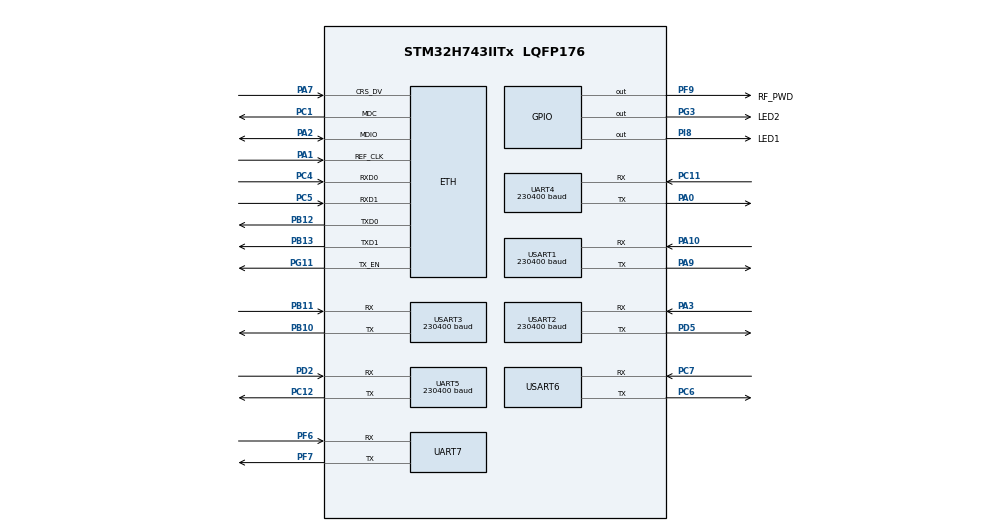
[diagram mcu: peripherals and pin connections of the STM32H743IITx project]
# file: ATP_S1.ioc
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CORTEX_M7.AccessPermission_S-Cortex_Memory_Protection_Unit_Region1_Settings_S=MPU_REGION_FULL_ACCESS
CORTEX_M7.BaseAddress_S-Cortex_Memory_Protection_Unit_Region1_Settings_S=0x30000000
CORTEX_M7.CPU_DCache=Enabled
CORTEX_M7.CPU_ICache=Enabled
CORTEX_M7.DisableExec_S-Cortex_Memory_Protection_Unit_Region1_Settings_S=MPU_INSTRUCTION_ACCESS_DISABLE
CORTEX_M7.Enable_S-Cortex_Memory_Protection_Unit_Region1_Settings_S=MPU_REGION_ENABLE
CORTEX_M7.IsShareable_S-Cortex_Memory_Protection_Unit_Region1_Settings_S=MPU_ACCESS_SHAREABLE
CORTEX_M7.Size_S-Cortex_Memory_Protection_Unit_Region1_Settings_S=MPU_REGION_SIZE_32KB
CORTEX_M7.TypeExtField_S-Cortex_Memory_Protection_Unit_Region1_Settings_S=MPU_TEX_LEVEL1
CORTEX_M7.default_mode_Activation=1
Dma.Request0=USART2_RX
Dma.Request1=USART2_TX
Dma.Request10=UART7_RX
Dma.Request11=UART7_TX
Dma.Request2=USART3_RX
Dma.Request3=USART3_TX
Dma.Request4=USART6_RX
Dma.Request5=USART6_TX
Dma.Request6=UART4_RX
Dma.Request7=UART4_TX
Dma.Request8=UART5_RX
Dma.Request9=UART5_TX
Dma.UART4_RX.6.Direction=DMA_PERIPH_TO_MEMORY
Dma.UART4_RX.6.EventEnable=DISABLE
Dma.UART4_RX.6.FIFOMode=DMA_FIFOMODE_DISABLE
Dma.UART4_RX.6.Instance=DMA1_Stream6
Dma.UART4_RX.6.MemDataAlignment=DMA_MDATAALIGN_BYTE
Dma.UART4_RX.6.MemInc=DMA_MINC_ENABLE
Dma.UART4_RX.6.Mode=DMA_NORMAL
Dma.UART4_RX.6.PeriphDataAlignment=DMA_PDATAALIGN_BYTE
Dma.UART4_RX.6.PeriphInc=DMA_PINC_DISABLE
Dma.UART4_RX.6.Polarity=HAL_DMAMUX_REQ_GEN_RISING
Dma.UART4_RX.6.Priority=DMA_PRIORITY_LOW
Dma.UART4_RX.6.RequestNumber=1
Dma.UART4_RX.6.SignalID=NONE
Dma.UART4_RX.6.SyncEnable=DISABLE
Dma.UART4_RX.6.SyncPolarity=HAL_DMAMUX_SYNC_NO_EVENT
Dma.UART4_RX.6.SyncRequestNumber=1
Dma.UART4_RX.6.SyncSignalID=NONE
Dma.UART4_TX.7.Direction=DMA_MEMORY_TO_PERIPH
Dma.UART4_TX.7.EventEnable=DISABLE
Dma.UART4_TX.7.FIFOMode=DMA_FIFOMODE_DISABLE
Dma.UART4_TX.7.Instance=DMA1_Stream7
Dma.UART4_TX.7.MemDataAlignment=DMA_MDATAALIGN_BYTE
Dma.UART4_TX.7.MemInc=DMA_MINC_ENABLE
Dma.UART4_TX.7.Mode=DMA_NORMAL
Dma.UART4_TX.7.PeriphDataAlignment=DMA_PDATAALIGN_BYTE
Dma.UART4_TX.7.PeriphInc=DMA_PINC_DISABLE
Dma.UART4_TX.7.Polarity=HAL_DMAMUX_REQ_GEN_RISING
Dma.UART4_TX.7.Priority=DMA_PRIORITY_LOW
Dma.UART4_TX.7.RequestNumber=1
Dma.UART4_TX.7.SignalID=NONE
Dma.UART4_TX.7.SyncEnable=DISABLE
Dma.UART4_TX.7.SyncPolarity=HAL_DMAMUX_SYNC_NO_EVENT
Dma.UART4_TX.7.SyncRequestNumber=1
Dma.UART4_TX.7.SyncSignalID=NONE
Dma.UART5_RX.8.Direction=DMA_PERIPH_TO_MEMORY
Dma.UART5_RX.8.EventEnable=DISABLE
Dma.UART5_RX.8.FIFOMode=DMA_FIFOMODE_DISABLE
Dma.UART5_RX.8.Instance=DMA2_Stream0
Dma.UART5_RX.8.MemDataAlignment=DMA_MDATAALIGN_BYTE
Dma.UART5_RX.8.MemInc=DMA_MINC_ENABLE
Dma.UART5_RX.8.Mode=DMA_NORMAL
Dma.UART5_RX.8.PeriphDataAlignment=DMA_PDATAALIGN_BYTE
Dma.UART5_RX.8.PeriphInc=DMA_PINC_DISABLE
Dma.UART5_RX.8.Polarity=HAL_DMAMUX_REQ_GEN_RISING
Dma.UART5_RX.8.Priority=DMA_PRIORITY_LOW
Dma.UART5_RX.8.RequestNumber=1
Dma.UART5_RX.8.SignalID=NONE
Dma.UART5_RX.8.SyncEnable=DISABLE
Dma.UART5_RX.8.SyncPolarity=HAL_DMAMUX_SYNC_NO_EVENT
Dma.UART5_RX.8.SyncRequestNumber=1
Dma.UART5_RX.8.SyncSignalID=NONE
Dma.UART5_TX.9.Direction=DMA_MEMORY_TO_PERIPH
Dma.UART5_TX.9.EventEnable=DISABLE
Dma.UART5_TX.9.FIFOMode=DMA_FIFOMODE_DISABLE
Dma.UART5_TX.9.Instance=DMA2_Stream1
Dma.UART5_TX.9.MemDataAlignment=DMA_MDATAALIGN_BYTE
Dma.UART5_TX.9.MemInc=DMA_MINC_ENABLE
Dma.UART5_TX.9.Mode=DMA_NORMAL
Dma.UART5_TX.9.PeriphDataAlignment=DMA_PDATAALIGN_BYTE
Dma.UART5_TX.9.PeriphInc=DMA_PINC_DISABLE
Dma.UART5_TX.9.Polarity=HAL_DMAMUX_REQ_GEN_RISING
Dma.UART5_TX.9.Priority=DMA_PRIORITY_LOW
Dma.UART5_TX.9.RequestNumber=1
Dma.UART5_TX.9.SignalID=NONE
Dma.UART5_TX.9.SyncEnable=DISABLE
Dma.UART5_TX.9.SyncPolarity=HAL_DMAMUX_SYNC_NO_EVENT
Dma.UART5_TX.9.SyncRequestNumber=1
Dma.UART5_TX.9.SyncSignalID=NONE
Dma.UART7_RX.10.Direction=DMA_PERIPH_TO_MEMORY
Dma.UART7_RX.10.EventEnable=DISABLE
Dma.UART7_RX.10.FIFOMode=DMA_FIFOMODE_DISABLE
Dma.UART7_RX.10.Instance=DMA2_Stream2
Dma.UART7_RX.10.MemDataAlignment=DMA_MDATAALIGN_BYTE
Dma.UART7_RX.10.MemInc=DMA_MINC_ENABLE
Dma.UART7_RX.10.Mode=DMA_NORMAL
Dma.UART7_RX.10.PeriphDataAlignment=DMA_PDATAALIGN_BYTE
Dma.UART7_RX.10.PeriphInc=DMA_PINC_DISABLE
Dma.UART7_RX.10.Polarity=HAL_DMAMUX_REQ_GEN_RISING
Dma.UART7_RX.10.Priority=DMA_PRIORITY_LOW
Dma.UART7_RX.10.RequestNumber=1
Dma.UART7_RX.10.SignalID=NONE
Dma.UART7_RX.10.SyncEnable=DISABLE
Dma.UART7_RX.10.SyncPolarity=HAL_DMAMUX_SYNC_NO_EVENT
Dma.UART7_RX.10.SyncRequestNumber=1
Dma.UART7_RX.10.SyncSignalID=NONE
Dma.UART7_TX.11.Direction=DMA_MEMORY_TO_PERIPH
Dma.UART7_TX.11.EventEnable=DISABLE
Dma.UART7_TX.11.FIFOMode=DMA_FIFOMODE_DISABLE
Dma.UART7_TX.11.Instance=DMA2_Stream3
Dma.UART7_TX.11.MemDataAlignment=DMA_MDATAALIGN_BYTE
Dma.UART7_TX.11.MemInc=DMA_MINC_ENABLE
Dma.UART7_TX.11.Mode=DMA_NORMAL
Dma.UART7_TX.11.PeriphDataAlignment=DMA_PDATAALIGN_BYTE
Dma.UART7_TX.11.PeriphInc=DMA_PINC_DISABLE
Dma.UART7_TX.11.Polarity=HAL_DMAMUX_REQ_GEN_RISING
Dma.UART7_TX.11.Priority=DMA_PRIORITY_LOW
Dma.UART7_TX.11.RequestNumber=1
Dma.UART7_TX.11.SignalID=NONE
Dma.UART7_TX.11.SyncEnable=DISABLE
Dma.UART7_TX.11.SyncPolarity=HAL_DMAMUX_SYNC_NO_EVENT
Dma.UART7_TX.11.SyncRequestNumber=1
Dma.UART7_TX.11.SyncSignalID=NONE
Dma.USART2_RX.0.Direction=DMA_PERIPH_TO_MEMORY
Dma.USART2_RX.0.EventEnable=DISABLE
Dma.USART2_RX.0.FIFOMode=DMA_FIFOMODE_DISABLE
Dma.USART2_RX.0.Instance=DMA1_Stream0
Dma.USART2_RX.0.MemDataAlignment=DMA_MDATAALIGN_BYTE
Dma.USART2_RX.0.MemInc=DMA_MINC_ENABLE
Dma.USART2_RX.0.Mode=DMA_NORMAL
Dma.USART2_RX.0.PeriphDataAlignment=DMA_PDATAALIGN_BYTE
Dma.USART2_RX.0.PeriphInc=DMA_PINC_DISABLE
Dma.USART2_RX.0.Polarity=HAL_DMAMUX_REQ_GEN_RISING
Dma.USART2_RX.0.Priority=DMA_PRIORITY_LOW
Dma.USART2_RX.0.RequestNumber=1
Dma.USART2_RX.0.SignalID=NONE
Dma.USART2_RX.0.SyncEnable=DISABLE
Dma.USART2_RX.0.SyncPolarity=HAL_DMAMUX_SYNC_NO_EVENT
Dma.USART2_RX.0.SyncRequestNumber=1
Dma.USART2_RX.0.SyncSignalID=NONE
Dma.USART2_TX.1.Direction=DMA_MEMORY_TO_PERIPH
Dma.USART2_TX.1.EventEnable=DISABLE
Dma.USART2_TX.1.FIFOMode=DMA_FIFOMODE_DISABLE
Dma.USART2_TX.1.Instance=DMA1_Stream1
Dma.USART2_TX.1.MemDataAlignment=DMA_MDATAALIGN_BYTE
Dma.USART2_TX.1.MemInc=DMA_MINC_ENABLE
Dma.USART2_TX.1.Mode=DMA_NORMAL
Dma.USART2_TX.1.PeriphDataAlignment=DMA_PDATAALIGN_BYTE
Dma.USART2_TX.1.PeriphInc=DMA_PINC_DISABLE
Dma.USART2_TX.1.Polarity=HAL_DMAMUX_REQ_GEN_RISING
Dma.USART2_TX.1.Priority=DMA_PRIORITY_LOW
Dma.USART2_TX.1.RequestNumber=1
Dma.USART2_TX.1.SignalID=NONE
Dma.USART2_TX.1.SyncEnable=DISABLE
Dma.USART2_TX.1.SyncPolarity=HAL_DMAMUX_SYNC_NO_EVENT
Dma.USART2_TX.1.SyncRequestNumber=1
Dma.USART2_TX.1.SyncSignalID=NONE
Dma.USART3_RX.2.Direction=DMA_PERIPH_TO_MEMORY
Dma.USART3_RX.2.EventEnable=DISABLE
Dma.USART3_RX.2.FIFOMode=DMA_FIFOMODE_DISABLE
Dma.USART3_RX.2.Instance=DMA1_Stream2
Dma.USART3_RX.2.MemDataAlignment=DMA_MDATAALIGN_BYTE
Dma.USART3_RX.2.MemInc=DMA_MINC_ENABLE
Dma.USART3_RX.2.Mode=DMA_NORMAL
Dma.USART3_RX.2.PeriphDataAlignment=DMA_PDATAALIGN_BYTE
Dma.USART3_RX.2.PeriphInc=DMA_PINC_DISABLE
Dma.USART3_RX.2.Polarity=HAL_DMAMUX_REQ_GEN_RISING
Dma.USART3_RX.2.Priority=DMA_PRIORITY_LOW
Dma.USART3_RX.2.RequestNumber=1
Dma.USART3_RX.2.SignalID=NONE
Dma.USART3_RX.2.SyncEnable=DISABLE
Dma.USART3_RX.2.SyncPolarity=HAL_DMAMUX_SYNC_NO_EVENT
Dma.USART3_RX.2.SyncRequestNumber=1
Dma.USART3_RX.2.SyncSignalID=NONE
Dma.USART3_TX.3.Direction=DMA_MEMORY_TO_PERIPH
Dma.USART3_TX.3.EventEnable=DISABLE
Dma.USART3_TX.3.FIFOMode=DMA_FIFOMODE_DISABLE
Dma.USART3_TX.3.Instance=DMA1_Stream3
Dma.USART3_TX.3.MemDataAlignment=DMA_MDATAALIGN_BYTE
Dma.USART3_TX.3.MemInc=DMA_MINC_ENABLE
Dma.USART3_TX.3.Mode=DMA_NORMAL
Dma.USART3_TX.3.PeriphDataAlignment=DMA_PDATAALIGN_BYTE
Dma.USART3_TX.3.PeriphInc=DMA_PINC_DISABLE
Dma.USART3_TX.3.Polarity=HAL_DMAMUX_REQ_GEN_RISING
Dma.USART3_TX.3.Priority=DMA_PRIORITY_LOW
Dma.USART3_TX.3.RequestNumber=1
Dma.USART3_TX.3.SignalID=NONE
Dma.USART3_TX.3.SyncEnable=DISABLE
Dma.USART3_TX.3.SyncPolarity=HAL_DMAMUX_SYNC_NO_EVENT
Dma.USART3_TX.3.SyncRequestNumber=1
Dma.USART3_TX.3.SyncSignalID=NONE
Dma.USART6_RX.4.Direction=DMA_PERIPH_TO_MEMORY
Dma.USART6_RX.4.EventEnable=DISABLE
Dma.USART6_RX.4.FIFOMode=DMA_FIFOMODE_DISABLE
Dma.USART6_RX.4.Instance=DMA1_Stream4
Dma.USART6_RX.4.MemDataAlignment=DMA_MDATAALIGN_BYTE
Dma.USART6_RX.4.MemInc=DMA_MINC_ENABLE
Dma.USART6_RX.4.Mode=DMA_NORMAL
Dma.USART6_RX.4.PeriphDataAlignment=DMA_PDATAALIGN_BYTE
Dma.USART6_RX.4.PeriphInc=DMA_PINC_DISABLE
Dma.USART6_RX.4.Polarity=HAL_DMAMUX_REQ_GEN_RISING
Dma.USART6_RX.4.Priority=DMA_PRIORITY_LOW
Dma.USART6_RX.4.RequestNumber=1
Dma.USART6_RX.4.SignalID=NONE
Dma.USART6_RX.4.SyncEnable=DISABLE
Dma.USART6_RX.4.SyncPolarity=HAL_DMAMUX_SYNC_NO_EVENT
Dma.USART6_RX.4.SyncRequestNumber=1
Dma.USART6_RX.4.SyncSignalID=NONE
Dma.USART6_TX.5.Direction=DMA_MEMORY_TO_PERIPH
Dma.USART6_TX.5.EventEnable=DISABLE
Dma.USART6_TX.5.FIFOMode=DMA_FIFOMODE_DISABLE
Dma.USART6_TX.5.Instance=DMA1_Stream5
Dma.USART6_TX.5.MemDataAlignment=DMA_MDATAALIGN_BYTE
Dma.USART6_TX.5.MemInc=DMA_MINC_ENABLE
Dma.USART6_TX.5.Mode=DMA_NORMAL
Dma.USART6_TX.5.PeriphDataAlignment=DMA_PDATAALIGN_BYTE
Dma.USART6_TX.5.PeriphInc=DMA_PINC_DISABLE
Dma.USART6_TX.5.Polarity=HAL_DMAMUX_REQ_GEN_RISING
Dma.USART6_TX.5.Priority=DMA_PRIORITY_LOW
Dma.USART6_TX.5.RequestNumber=1
Dma.USART6_TX.5.SignalID=NONE
Dma.USART6_TX.5.SyncEnable=DISABLE
Dma.USART6_TX.5.SyncPolarity=HAL_DMAMUX_SYNC_NO_EVENT
Dma.USART6_TX.5.SyncRequestNumber=1
Dma.USART6_TX.5.SyncSignalID=NONE
ETH.MediaInterface=HAL_ETH_RMII_MODE
FREERTOS.BinarySemaphores01=BinaryServo,Dynamic,NULL,Available;BinaryCu,Dynamic,NULL,Available;BinaryJing,Dynamic,NULL,Available;BinaryFocus,Dynamic,NULL,Available;BinaryRangefinder,Dynamic,NULL,Available
FREERTOS.Tasks01=defaultTask,0,256,StartDefaultTask,Default,NULL,Dynamic,NULL,NULL;turn,-1,256,TurnTask,Default,NULL,Dynamic,NULL,NULL;imgcu,-1,256,ImgCuTask,Default,NULL,Dynamic,NULL,NULL;imgjing,-1,256,ImgJingTask,Default,NULL,Dynamic,NULL,NULL;focus,-1,256,FocusTask,Default,NULL,Dynamic,NULL,NULL;rangefinder,-1,256,RangefinderTask,Default,NULL,Dynamic,NULL,NULL
FREERTOS.configTOTAL_HEAP_SIZE=30720
LWIP.BSP.number=1
LWIP.GATEWAY_ADDRESS=192.168.000.001
LWIP.IP_ADDRESS=192.168.000.100
LWIP.LWIP_DHCP=0
LWIP.LWIP_RAM_HEAP_POINTER=0x30002000
LWIP.MEM_SIZE=10*1024
LWIP.NETMASK_ADDRESS=255.255.255.000
LWIP.Version=v2.1.2_Cube
LWIP0.BSP.STBoard=false
LWIP0.BSP.api=BSP_COMPONENT_DRIVER
LWIP0.BSP.component=LAN8742
LWIP0.BSP.instance=LAN8742
LWIP0.BSP.name=Driver_PHY
LWIP0.BSP.semaphore=S_LAN8742
LWIP0.BSP.solution=LAN8742
Mcu.Family=STM32H7
Mcu.Name=STM32H743IITx
Mcu.Package=LQFP176
NVIC.DMA1_Stream0_IRQn=true\:5\:0\:false\:false\:true\:true\:false\:true\:true
NVIC.DMA1_Stream1_IRQn=true\:5\:0\:false\:false\:true\:true\:false\:true\:true
NVIC.DMA1_Stream2_IRQn=true\:5\:0\:false\:false\:true\:true\:false\:true\:true
NVIC.DMA1_Stream3_IRQn=true\:5\:0\:false\:false\:true\:true\:false\:true\:true
NVIC.DMA1_Stream4_IRQn=true\:5\:0\:false\:false\:true\:true\:false\:true\:true
NVIC.DMA1_Stream5_IRQn=true\:5\:0\:false\:false\:true\:true\:false\:true\:true
NVIC.DMA1_Stream6_IRQn=true\:5\:0\:false\:false\:true\:true\:false\:true\:true
NVIC.DMA1_Stream7_IRQn=true\:5\:0\:false\:false\:true\:true\:false\:true\:true
NVIC.DMA2_Stream0_IRQn=true\:5\:0\:false\:false\:true\:true\:false\:true\:true
NVIC.DMA2_Stream1_IRQn=true\:5\:0\:false\:false\:true\:true\:false\:true\:true
NVIC.DMA2_Stream2_IRQn=true\:5\:0\:false\:false\:true\:true\:false\:true\:true
NVIC.DMA2_Stream3_IRQn=true\:5\:0\:false\:false\:true\:true\:false\:true\:true
NVIC.ETH_IRQn=true\:5\:0\:false\:false\:true\:true\:true\:true\:true
NVIC.PriorityGroup=NVIC_PRIORITYGROUP_4
NVIC.TIM6_DAC_IRQn=true\:15\:0\:false\:false\:true\:false\:false\:true\:true
NVIC.TimeBase=TIM6_DAC_IRQn
NVIC.TimeBaseIP=TIM6
NVIC.UART4_IRQn=true\:5\:0\:false\:false\:true\:true\:true\:true\:true
NVIC.UART5_IRQn=true\:5\:0\:false\:false\:true\:true\:true\:true\:true
NVIC.UART7_IRQn=true\:5\:0\:false\:false\:true\:true\:true\:true\:true
NVIC.USART2_IRQn=true\:5\:0\:false\:false\:true\:true\:true\:true\:true
NVIC.USART3_IRQn=true\:5\:0\:false\:false\:true\:true\:true\:true\:true
NVIC.USART6_IRQn=true\:5\:0\:false\:false\:true\:true\:true\:true\:true
PA0.Mode=Asynchronous
PA0.Signal=UART4_TX
PA1.GPIO_Speed=GPIO_SPEED_FREQ_VERY_HIGH
PA1.Mode=RMII
PA1.Signal=ETH_REF_CLK
PA10.Mode=Asynchronous
PA10.Signal=USART1_RX
PA2.GPIO_Speed=GPIO_SPEED_FREQ_VERY_HIGH
PA2.Mode=RMII
PA2.Signal=ETH_MDIO
PA3.Mode=Asynchronous
PA3.Signal=USART2_RX
PA7.GPIO_Speed=GPIO_SPEED_FREQ_VERY_HIGH
PA7.Mode=RMII
PA7.Signal=ETH_CRS_DV
PA9.Mode=Asynchronous
PA9.Signal=USART1_TX
PB10.Mode=Asynchronous
PB10.Signal=USART3_TX
PB11.Mode=Asynchronous
PB11.Signal=USART3_RX
PB12.GPIO_Speed=GPIO_SPEED_FREQ_VERY_HIGH
PB12.Mode=RMII
PB12.Signal=ETH_TXD0
PB13.GPIO_Speed=GPIO_SPEED_FREQ_VERY_HIGH
PB13.Mode=RMII
PB13.Signal=ETH_TXD1
PC1.GPIO_Speed=GPIO_SPEED_FREQ_VERY_HIGH
PC1.Mode=RMII
PC1.Signal=ETH_MDC
PC11.Mode=Asynchronous
PC11.Signal=UART4_RX
PC12.Mode=Asynchronous
PC12.Signal=UART5_TX
PC4.GPIO_Speed=GPIO_SPEED_FREQ_VERY_HIGH
PC4.Mode=RMII
PC4.Signal=ETH_RXD0
PC5.GPIO_Speed=GPIO_SPEED_FREQ_VERY_HIGH
PC5.Mode=RMII
PC5.Signal=ETH_RXD1
PC6.Mode=Asynchronous
PC6.Signal=USART6_TX
PC7.Mode=Asynchronous
PC7.Signal=USART6_RX
PD2.Mode=Asynchronous
PD2.Signal=UART5_RX
PD5.Mode=Asynchronous
PD5.Signal=USART2_TX
PF6.Mode=Asynchronous
PF6.Signal=UART7_RX
PF7.Mode=Asynchronous
PF7.Signal=UART7_TX
PF9.GPIO_Label=RF_PWD
PF9.Signal=GPIO_Output
PG11.GPIO_Speed=GPIO_SPEED_FREQ_VERY_HIGH
PG11.Mode=RMII
PG11.Signal=ETH_TX_EN
PG3.GPIO_Label=LED2
PG3.Signal=GPIO_Output
PH0-OSC_IN\ (PH0).Mode=HSE-External-Oscillator
PH0-OSC_IN\ (PH0).Signal=RCC_OSC_IN
PH1-OSC_OUT\ (PH1).Mode=HSE-External-Oscillator
PH1-OSC_OUT\ (PH1).Signal=RCC_OSC_OUT
PI8.GPIO_Label=LED1
PI8.Signal=GPIO_Output
ProjectManager.HeapSize=0x200
ProjectManager.StackSize=0x400
ProjectManager.TargetToolchain=STM32CubeIDE
RCC.ADCFreq_Value=129000000
RCC.APB1Freq_Value=120000000
RCC.APB2Freq_Value=120000000
RCC.APB3Freq_Value=120000000
RCC.APB4Freq_Value=120000000
RCC.CortexFreq_Value=480000000
RCC.D1PPRE=RCC_APB3_DIV2
RCC.D2PPRE1=RCC_APB1_DIV2
RCC.D2PPRE2=RCC_APB2_DIV2
RCC.D3PPRE=RCC_APB4_DIV2
RCC.DIVM1=4
RCC.DIVN1=60
RCC.HCLKFreq_Value=240000000
RCC.HPRE=RCC_HCLK_DIV2
RCC.PLL2FRACN=0
RCC.PLL3FRACN=0
RCC.PLLFRACN=0
RCC.SYSCLKFreq_VALUE=480000000
RCC.SYSCLKSource=RCC_SYSCLKSOURCE_PLLCLK
RCC.USBFreq_Value=480000000
UART4.BaudRate=230400
UART5.BaudRate=230400
USART1.BaudRate=230400
USART1.VirtualMode-Asynchronous=VM_ASYNC
USART2.BaudRate=230400
USART2.VirtualMode-Asynchronous=VM_ASYNC
USART3.BaudRate=230400
USART3.VirtualMode-Asynchronous=VM_ASYNC
USART6.VirtualMode-Asynchronous=VM_ASYNC
VP_FREERTOS_VS_CMSIS_V1.Mode=CMSIS_V1
VP_LWIP_VS_Enabled.Mode=Enabled
VP_MEMORYMAP_VS_MEMORYMAP.Mode=CurAppReg
VP_SYS_VS_tim6.Mode=TIM6
board=custom

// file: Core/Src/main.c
/* USER CODE BEGIN Header */
/**
  ******************************************************************************
  * @file           : main.c
  * @brief          : Main program body
  ******************************************************************************
  * @attention
  *
  * Copyright (c) 2024 STMicroelectronics.
  * All rights reserved.
  *
  * This software is licensed under terms that can be found in the LICENSE file
  * in the root directory of this software component.
  * If no LICENSE file comes with this software, it is provided AS-IS.
  *
  ******************************************************************************
  */
/* USER CODE END Header */
#include "main.h"
#include "cmsis_os.h"
#include "dma.h"
#include "lwip.h"
#include "memorymap.h"
#include "usart.h"
#include "gpio.h"

void SystemClock_Config(void);
static void MPU_Config(void);
void MX_FREERTOS_Init(void);

/* USER CODE BEGIN 0 */
__attribute__((section("._Text_Area"))) static char buff[128];

int uart_printf(const char *fmt, ...){
//  static char buff[128];
  va_list va;int ret;
  va_start(va, fmt);
  ret = vsprintf(buff, fmt, va);
  va_end(va);
  if (ret > 0){
    HAL_UART_Transmit(&huart1, (uint8_t*)buff, ret, HAL_MAX_DELAY);
  }
  return ret;
}

void DelayMs(uint32_t ms) {
    uint32_t startTick = HAL_GetTick();  // 记录当前SysTick�?
    while ((HAL_GetTick() - startTick) < ms) {
        // 忙等�?
    }
}
/* USER CODE END 0 */

int main(void)
{

  /* MPU Configuration--------------------------------------------------------*/
  MPU_Config();

  /* Enable the CPU Cache */

  /* Enable I-Cache---------------------------------------------------------*/
  SCB_EnableICache();

  /* Enable D-Cache---------------------------------------------------------*/
  SCB_EnableDCache();

  /* MCU Configuration--------------------------------------------------------*/

  /* Reset of all peripherals, Initializes the Flash interface and the Systick. */
  HAL_Init();

  /* Configure the system clock */
  SystemClock_Config();

  /* Initialize all configured peripherals */
  MX_GPIO_Init();
  MX_DMA_Init();
  MX_USART1_UART_Init();
  MX_USART2_UART_Init();
  MX_USART3_UART_Init();
  MX_USART6_UART_Init();
  MX_UART4_Init();
  MX_UART5_Init();
  MX_UART7_Init();
  /* USER CODE BEGIN 2 */
  HAL_Delay(2000);
//  uart_printf("hello world");
//  HAL_GPIO_TogglePin(LED2_GPIO_Port, LED2_Pin);
  /* USER CODE END 2 */

  /* Call init function for freertos objects (in cmsis_os2.c) */
  MX_FREERTOS_Init();

  /* Start scheduler */
  osKernelStart();

  /* We should never get here as control is now taken by the scheduler */

  /* Infinite loop */
  while (1)
  {

  }
}

void SystemClock_Config(void)
{
  RCC_OscInitTypeDef RCC_OscInitStruct = {0};
  RCC_ClkInitTypeDef RCC_ClkInitStruct = {0};

  /** Supply configuration update enable
  */
  HAL_PWREx_ConfigSupply(PWR_LDO_SUPPLY);

  /** Configure the main internal regulator output voltage
  */
  __HAL_PWR_VOLTAGESCALING_CONFIG(PWR_REGULATOR_VOLTAGE_SCALE1);

  while(!__HAL_PWR_GET_FLAG(PWR_FLAG_VOSRDY)) {}

  __HAL_RCC_SYSCFG_CLK_ENABLE();
  __HAL_PWR_VOLTAGESCALING_CONFIG(PWR_REGULATOR_VOLTAGE_SCALE0);

  while(!__HAL_PWR_GET_FLAG(PWR_FLAG_VOSRDY)) {}

  /** Initializes the RCC Oscillators according to the specified parameters
  * in the RCC_OscInitTypeDef structure.
  */
  RCC_OscInitStruct.OscillatorType = RCC_OSCILLATORTYPE_HSI;
  RCC_OscInitStruct.HSIState = RCC_HSI_DIV1;
  RCC_OscInitStruct.HSICalibrationValue = RCC_HSICALIBRATION_DEFAULT;
  RCC_OscInitStruct.PLL.PLLState = RCC_PLL_ON;
  RCC_OscInitStruct.PLL.PLLSource = RCC_PLLSOURCE_HSI;
  RCC_OscInitStruct.PLL.PLLM = 4;
  RCC_OscInitStruct.PLL.PLLN = 60;
  RCC_OscInitStruct.PLL.PLLP = 2;
  RCC_OscInitStruct.PLL.PLLQ = 2;
  RCC_OscInitStruct.PLL.PLLR = 2;
  RCC_OscInitStruct.PLL.PLLRGE = RCC_PLL1VCIRANGE_3;
  RCC_OscInitStruct.PLL.PLLVCOSEL = RCC_PLL1VCOWIDE;
  RCC_OscInitStruct.PLL.PLLFRACN = 0;
  if (HAL_RCC_OscConfig(&RCC_OscInitStruct) != HAL_OK)
  {
    Error_Handler();
  }

  /** Initializes the CPU, AHB and APB buses clocks
  */
  RCC_ClkInitStruct.ClockType = RCC_CLOCKTYPE_HCLK|RCC_CLOCKTYPE_SYSCLK
                              |RCC_CLOCKTYPE_PCLK1|RCC_CLOCKTYPE_PCLK2
                              |RCC_CLOCKTYPE_D3PCLK1|RCC_CLOCKTYPE_D1PCLK1;
  RCC_ClkInitStruct.SYSCLKSource = RCC_SYSCLKSOURCE_PLLCLK;
  RCC_ClkInitStruct.SYSCLKDivider = RCC_SYSCLK_DIV1;
  RCC_ClkInitStruct.AHBCLKDivider = RCC_HCLK_DIV2;
  RCC_ClkInitStruct.APB3CLKDivider = RCC_APB3_DIV2;
  RCC_ClkInitStruct.APB1CLKDivider = RCC_APB1_DIV2;
  RCC_ClkInitStruct.APB2CLKDivider = RCC_APB2_DIV2;
  RCC_ClkInitStruct.APB4CLKDivider = RCC_APB4_DIV2;

  if (HAL_RCC_ClockConfig(&RCC_ClkInitStruct, FLASH_LATENCY_4) != HAL_OK)
  {
    Error_Handler();
  }
}

 /* MPU Configuration */

void MPU_Config(void)
{
  MPU_Region_InitTypeDef MPU_InitStruct = {0};

  /* Disables the MPU */
  HAL_MPU_Disable();

  /** Initializes and configures the Region and the memory to be protected
  */
  MPU_InitStruct.Enable = MPU_REGION_ENABLE;
  MPU_InitStruct.Number = MPU_REGION_NUMBER0;
  MPU_InitStruct.BaseAddress = 0x0;
  MPU_InitStruct.Size = MPU_REGION_SIZE_4GB;
  MPU_InitStruct.SubRegionDisable = 0x87;
  MPU_InitStruct.TypeExtField = MPU_TEX_LEVEL0;
  MPU_InitStruct.AccessPermission = MPU_REGION_NO_ACCESS;
  MPU_InitStruct.DisableExec = MPU_INSTRUCTION_ACCESS_DISABLE;
  MPU_InitStruct.IsShareable = MPU_ACCESS_SHAREABLE;
  MPU_InitStruct.IsCacheable = MPU_ACCESS_NOT_CACHEABLE;
  MPU_InitStruct.IsBufferable = MPU_ACCESS_NOT_BUFFERABLE;

  HAL_MPU_ConfigRegion(&MPU_InitStruct);

  /** Initializes and configures the Region and the memory to be protected
  */
  MPU_InitStruct.Number = MPU_REGION_NUMBER1;
  MPU_InitStruct.BaseAddress = 0x30000000;
  MPU_InitStruct.Size = MPU_REGION_SIZE_32KB;
  MPU_InitStruct.SubRegionDisable = 0x0;
  MPU_InitStruct.TypeExtField = MPU_TEX_LEVEL1;
  MPU_InitStruct.AccessPermission = MPU_REGION_FULL_ACCESS;

  HAL_MPU_ConfigRegion(&MPU_InitStruct);
  /* Enables the MPU */
  HAL_MPU_Enable(MPU_PRIVILEGED_DEFAULT);

}

void HAL_TIM_PeriodElapsedCallback(TIM_HandleTypeDef *htim)
{
  if (htim->Instance == TIM6) {
    HAL_IncTick();
  }
}

void Error_Handler(void)
{
  __disable_irq();
  while (1)
  {
  }
}

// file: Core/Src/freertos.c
/* USER CODE BEGIN Header */
/**
  ******************************************************************************
  * File Name          : freertos.c
  * Description        : Code for freertos applications
  ******************************************************************************
  * @attention
  *
  * Copyright (c) 2024 STMicroelectronics.
  * All rights reserved.
  *
  * This software is licensed under terms that can be found in the LICENSE file
  * in the root directory of this software component.
  * If no LICENSE file comes with this software, it is provided AS-IS.
  *
  ******************************************************************************
  */
/* USER CODE END Header */

#include "FreeRTOS.h"
#include "task.h"
#include "main.h"
#include "cmsis_os.h"

/* USER CODE BEGIN Includes */
#include "ServoModule.h"
#include "ImageModule.h"
#include "RangefinderModule.h"
#include "Focus.h"
#include "tcpecho.h"
#include "cmdPC.h"
/* USER CODE END Includes */

/* USER CODE BEGIN PD */
uint8_t rxSize = 0;

/* USER CODE END PD */

/* USER CODE BEGIN PM */
BaseType_t taskTurnBegin = pdFALSE;
BaseType_t taskCuBegin = pdFALSE;
BaseType_t taskJingBegin = pdFALSE;
BaseType_t taskFocusBegin = pdFALSE;
BaseType_t taskRangeBegin = pdFALSE;

uint8_t InitFlag = 1;
/* USER CODE END PM */

/* USER CODE BEGIN Variables */
__attribute__((section("._Text_Area"))) uint8_t rxdata_servo[128];
__attribute__((section("._Text_Area"))) uint8_t rxbuff_servo[128];
__attribute__((section("._Text_Area"))) char msg[256];
__attribute__((section("._Text_Area"))) uint8_t rxdata_cu[128];
__attribute__((section("._Text_Area"))) uint8_t rxbuff_cu[128];
__attribute__((section("._Text_Area"))) uint8_t rxdata_jing[128];
__attribute__((section("._Text_Area"))) uint8_t rxbuff_jing[128];
__attribute__((section("._Text_Area"))) uint8_t rxdata_focus[11];
__attribute__((section("._Text_Area"))) uint8_t rxbuff_focus[11];
__attribute__((section("._Text_Area"))) uint8_t rxdata_rangefinder[128];
__attribute__((section("._Text_Area"))) uint8_t rxbuff_rangefinder[128];

__attribute__((section("._Text_Area"))) uint8_t chcmd[64];
// uint8_t uartbuff[128];

/* USER CODE END Variables */
osThreadId defaultTaskHandle;
osThreadId turnHandle;
osThreadId imgcuHandle;
osThreadId imgjingHandle;
osThreadId focusHandle;
osThreadId rangefinderHandle;
osSemaphoreId BinaryServoHandle;
osSemaphoreId BinaryCuHandle;
osSemaphoreId BinaryJingHandle;
osSemaphoreId BinaryFocusHandle;
osSemaphoreId BinaryRangefinderHandle;

osThreadId mytaskHandle; // 自己添加的任务句柄

void StartDefaultTask(void const * argument);
void TurnTask(void const * argument);
void ImgCuTask(void const * argument);
void ImgJingTask(void const * argument);
void FocusTask(void const * argument);
void RangefinderTask(void const * argument);

void mytask(void const * argument); // 自己添加的任务

extern void MX_LWIP_Init(void);
void MX_FREERTOS_Init(void); /* (MISRA C 2004 rule 8.1) */

/* GetIdleTaskMemory prototype (linked to static allocation support) */
void vApplicationGetIdleTaskMemory( StaticTask_t **ppxIdleTaskTCBBuffer, StackType_t **ppxIdleTaskStackBuffer, uint32_t *pulIdleTaskStackSize );

/* USER CODE BEGIN GET_IDLE_TASK_MEMORY */
static StaticTask_t xIdleTaskTCBBuffer;
static StackType_t xIdleStack[configMINIMAL_STACK_SIZE];

void vApplicationGetIdleTaskMemory( StaticTask_t **ppxIdleTaskTCBBuffer, StackType_t **ppxIdleTaskStackBuffer, uint32_t *pulIdleTaskStackSize )
{
  *ppxIdleTaskTCBBuffer = &xIdleTaskTCBBuffer;
  *ppxIdleTaskStackBuffer = &xIdleStack[0];
  *pulIdleTaskStackSize = configMINIMAL_STACK_SIZE;
  /* place for user code */
}
/* USER CODE END GET_IDLE_TASK_MEMORY */

void MX_FREERTOS_Init(void) {

  /* Create the semaphores(s) */
  /* definition and creation of BinaryServo */
  osSemaphoreDef(BinaryServo);
  BinaryServoHandle = osSemaphoreCreate(osSemaphore(BinaryServo), 1);

  /* definition and creation of BinaryCu */
  osSemaphoreDef(BinaryCu);
  BinaryCuHandle = osSemaphoreCreate(osSemaphore(BinaryCu), 1);

  /* definition and creation of BinaryJing */
  osSemaphoreDef(BinaryJing);
  BinaryJingHandle = osSemaphoreCreate(osSemaphore(BinaryJing), 1);

  /* definition and creation of BinaryFocus */
  osSemaphoreDef(BinaryFocus);
  BinaryFocusHandle = osSemaphoreCreate(osSemaphore(BinaryFocus), 1);

  /* definition and creation of BinaryRangefinder */
  osSemaphoreDef(BinaryRangefinder);
  BinaryRangefinderHandle = osSemaphoreCreate(osSemaphore(BinaryRangefinder), 1);

  /* Create the thread(s) */
  /* definition and creation of defaultTask */
  osThreadDef(defaultTask, StartDefaultTask, osPriorityNormal, 0, 256);
  defaultTaskHandle = osThreadCreate(osThread(defaultTask), NULL);

  /* definition and creation of turn */
  osThreadDef(turn, TurnTask, osPriorityBelowNormal, 0, 256);
  turnHandle = osThreadCreate(osThread(turn), NULL);

  /* definition and creation of imgcu */
  osThreadDef(imgcu, ImgCuTask, osPriorityBelowNormal, 0, 256);
  imgcuHandle = osThreadCreate(osThread(imgcu), NULL);

  /* definition and creation of imgjing */
  osThreadDef(imgjing, ImgJingTask, osPriorityBelowNormal, 0, 256);
  imgjingHandle = osThreadCreate(osThread(imgjing), NULL);

  /* definition and creation of focus */
  osThreadDef(focus, FocusTask, osPriorityBelowNormal, 0, 256);
  focusHandle = osThreadCreate(osThread(focus), NULL);

  /* definition and creation of rangefinder */
  osThreadDef(rangefinder, RangefinderTask, osPriorityBelowNormal, 0, 256);
  rangefinderHandle = osThreadCreate(osThread(rangefinder), NULL);

  /* USER CODE BEGIN RTOS_THREADS */
  /* add threads, ... */
	osThreadDef(mytask, mytask, osPriorityNormal, 0, 256);
	mytaskHandle = osThreadCreate(osThread(mytask), NULL);

  /* USER CODE END RTOS_THREADS */

}

void StartDefaultTask(void const * argument)
{
  /* init code for LWIP */
  memset(ImgSendTypedef_CU.Data,0xff,64);
  memset(ImgSendTypedef_JING.Data,0xff,64);
  MX_LWIP_Init();
  /* USER CODE BEGIN StartDefaultTask */
//  client_init();
  udpecho_init();

	HAL_UARTEx_ReceiveToIdle_DMA(&huart5, rxbuff_servo, 128);
	__HAL_DMA_DISABLE_IT(&hdma_uart5_rx, DMA_IT_HT);
	HAL_UARTEx_ReceiveToIdle_DMA(&huart3, rxbuff_cu, 128);
	__HAL_DMA_DISABLE_IT(&hdma_usart3_rx, DMA_IT_HT);
	HAL_UARTEx_ReceiveToIdle_DMA(&huart4, rxbuff_jing, 128);
	__HAL_DMA_DISABLE_IT(&hdma_uart4_rx, DMA_IT_HT);
	HAL_UARTEx_ReceiveToIdle_DMA(&huart6, rxbuff_focus, 11);
	__HAL_DMA_DISABLE_IT(&hdma_usart6_rx, DMA_IT_HT);
	HAL_UARTEx_ReceiveToIdle_DMA(&huart7, rxbuff_rangefinder, 128);
	__HAL_DMA_DISABLE_IT(&hdma_uart7_rx, DMA_IT_HT);

	HAL_UARTEx_ReceiveToIdle_DMA(&huart2, (uint8_t *)chcmd, 64);
	__HAL_DMA_DISABLE_IT(&hdma_usart2_rx, DMA_IT_HT);

	HAL_GPIO_WritePin(RF_PWD_GPIO_Port,RF_PWD_Pin,GPIO_PIN_SET);
	// go2init();
	osDelay(1000);
	RangefinderDataFrameSend.FuncCode = SetMultiFreq;
	cSetMultiFreq = 0x0A;
	Send2RangefinderModule(&RangefinderDataFrameSend);
	osDelay(100);
	RangefinderDataFrameSend.FuncCode = SetTarget;
	cSetTarget = 0x01;
	Send2RangefinderModule(&RangefinderDataFrameSend);
//	osDelay(2000);
	vTaskSuspend(mytaskHandle);

  /* Infinite loop */
//	CommandTypedef.turnYaw.f = 30.f;
//	CommandTypedef.turnPitch.f = 60.f;
//	processControl();

  /* Infinite loop */
  for(;;)
  {
//	   if(InitFlag == 1)
	//   {
	// 	  	  state = STATE_GUIDE;
	// 		CommandTypedef.turnYaw.f = 30.f;
	// 		CommandTypedef.turnPitch.f = 60.f;
	// 		processControl();
	// 		InitFlag = 0;
	//   }

//	 if((taskCuBegin == pdTRUE) && (taskJingBegin == pdTRUE) && (InitFlag == 1))
	//  if((taskJingBegin == pdTRUE) && (InitFlag == 1))
	//  {
	//  	go2init();
	//  	InitFlag = 0;
	//  }else if(InitFlag == 0)
	//  {
		// uart2_printf("state:%d\n",state);
		// state = STATE_GUIDE;
		// HAL_GPIO_WritePin(LED2_GPIO_Port,LED2_Pin,GPIO_PIN_SET);
//	  if(InitFlag == 1)
//	  {
//		  go2init();
//		  InitFlag = 0;
//	  }
		processControl();
//	  Send2ImgModule(&ImgSendTypedef_CU,&ImgSendDataTypedef_CU);
	//  }

//	state = STATE_GUIDE;
//	CommandTypedef.turnYaw.f = 30.f;
//	CommandTypedef.turnPitch.f = 60.f;
//	processControl();
    osDelay(20);
  }
  /* USER CODE END StartDefaultTask */
}

void TurnTask(void const * argument)
{
  /* USER CODE BEGIN TurnTask */
  /* Infinite loop */
  for(;;)
  {
	  if(osSemaphoreWait(BinaryServoHandle, 10) == osOK && taskTurnBegin == pdTRUE)
	  {
		 pcSend.cuErrorCode[0]             			  = rxdata_servo[3];
		 pcSend.cuErrorCode[1]             			  = rxdata_servo[4];

		 TrackingFaultCodeCu.CommunicationFault       = (rxdata_servo[3] & bit(0)) ? 1 : 0;
		 TrackingFaultCodeCu.EncoderFault             = (rxdata_servo[3] & bit(1)) ? 1 : 0;
		 TrackingFaultCodeCu.DriverFaultA             = (rxdata_servo[3] & bit(2)) ? 1 : 0;
		 TrackingFaultCodeCu.DriverFaultE             = (rxdata_servo[3] & bit(3)) ? 1 : 0;
		 TrackingFaultCodeCu.OverSpeedA               = (rxdata_servo[3] & bit(4)) ? 1 : 0;
		 TrackingFaultCodeCu.OverSpeedE               = (rxdata_servo[3] & bit(5)) ? 1 : 0;
		 TrackingFaultCodeCu.ControlOverLimitA        = (rxdata_servo[3] & bit(6)) ? 1 : 0;
		 TrackingFaultCodeCu.ControlOverLimitE        = (rxdata_servo[3] & bit(7)) ? 1 : 0;
		 TrackingFaultCodeCu.PositionOverLimitE       = (rxdata_servo[4] & bit(0)) ? 1 : 0;
		 TrackingFaultCodeCu.PositionUnderLimitE      = (rxdata_servo[4] & bit(1)) ? 1 : 0;
		 TrackingFaultCodeCu.TrackingFaultCuByte1     = (rxdata_servo[4] & bit(2)) ? 1 : 0;
		 TrackingFaultCodeCu.TrackingFaultCuByte2     = (rxdata_servo[4] & bit(3)) ? 1 : 0;
		 TrackingFaultCodeCu.TrackingFaultCuByte3     = (rxdata_servo[4] & bit(4)) ? 1 : 0;
		 TrackingFaultCodeCu.TrackingFaultCuByte4     = (rxdata_servo[4] & bit(5)) ? 1 : 0;

		 pcSend.jingErrorCode[0]                      = rxdata_servo[5];
		 pcSend.jingErrorCode[1]                      = rxdata_servo[6];
		 TrackingFaultCodeJing.FSMControlOverLimitX   = (rxdata_servo[5] & bit(0)) ? 1 : 0;
		 TrackingFaultCodeJing.FSMControlOverLimitY   = (rxdata_servo[5] & bit(1)) ? 1 : 0;
		 TrackingFaultCodeJing.FSMPositionOverLimitX  = (rxdata_servo[6] & bit(0)) ? 1 : 0;
		 TrackingFaultCodeJing.FSMPositionOverLimitY  = (rxdata_servo[6] & bit(1)) ? 1 : 0;
		 TrackingFaultCodeJing.TrackingFaultJing      = (rxdata_servo[6] & bit(2)) ? 1 : 0;

		 ServoRevTypedef.cCuOffsetState               =  rxdata_servo[17];
		 pcSend.cuOffsetState = ServoRevTypedef.cCuOffsetState;
		 ServoRevTypedef.CuOffset_X.s                 =  rxdata_servo[18] << 8 | rxdata_servo[19];
		 ServoRevTypedef.CuOffset_Y.s                 =  rxdata_servo[20] << 8 | rxdata_servo[21];
		 ServoRevTypedef.cJingOffsetState             =  rxdata_servo[22];
		 pcSend.jingOffsetState = ServoRevTypedef.cJingOffsetState;
		 ServoRevTypedef.cJingISOffsetState           =  rxdata_servo[23];
		 ServoRevTypedef.JingOffset_X.s               =  rxdata_servo[24] << 8 | rxdata_servo[25];
		 ServoRevTypedef.JingOffset_Y.s               =  rxdata_servo[26] << 8 | rxdata_servo[27];
		 ServoRevTypedef.cTurnTableTrackState         =  rxdata_servo[28];
		 ServoRevTypedef.cFSMTrackState               =  rxdata_servo[29];
		 // ServoRevTypedef.cElectPositionState          =  rxdata_servo[30];
		 ServoRevTypedef.cTurnTableMotorPowerState    =  rxdata_servo[31];
		 ServoRevTypedef.cJingTrackControlState       =  rxdata_servo[32];
		 for(int i = 0;i < 4;i++)
		 {
		   #if TOP
		   ServoRevTypedef.FSMXPos.u8t[3-i] = rxdata_servo[33+i];
		   ServoRevTypedef.FSMYPos.u8t[3-i] = rxdata_servo[37+i];
		   ServoRevTypedef.ServoYawPos.u8t[3-i] = rxdata_servo[41+i];
		   ServoRevTypedef.ServoPitchPos.u8t[3-i] = rxdata_servo[45+i];
		   ServoRevTypedef.YawSpeed.u8t[3-i] = rxdata_servo[49+i];
		   ServoRevTypedef.PitchSpeed.u8t[3-i] = rxdata_servo[53+i];
		   ServoRevTypedef.FSMXPosZero.u8t[3-i] = rxdata_servo[57+i];
		   ServoRevTypedef.FSMYPosZero.u8t[3-i] = rxdata_servo[61+i];
		   ServoRevTypedef.TurnYawOutput.u8t[3-i] = rxdata_servo[65+i];
		   ServoRevTypedef.TurnPitchOutput.u8t[3-i] = rxdata_servo[69+i];
		   ServoRevTypedef.FSMXOutput.u8t[3-i] = rxdata_servo[73+i];
		   ServoRevTypedef.FSMYOutput.u8t[3-i] = rxdata_servo[77+i];
		   #else
		   ServoRevTypedef.FSMXPos.u8t[i] = rxdata_servo[33+i];
		   ServoRevTypedef.FSMYPos.u8t[i] = rxdata_servo[37+i];
		   ServoRevTypedef.ServoYawPos.u8t[i] = rxdata_servo[41+i];
		   ServoRevTypedef.ServoPitchPos.u8t[i] = rxdata_servo[45+i];
		   ServoRevTypedef.YawSpeed.u8t[i] = rxdata_servo[49+i];
		   ServoRevTypedef.PitchSpeed.u8t[i] = rxdata_servo[53+i];
		   ServoRevTypedef.FSMXPosZero.u8t[i] = rxdata_servo[57+i];
		   ServoRevTypedef.FSMYPosZero.u8t[i] = rxdata_servo[61+i];
		   ServoRevTypedef.TurnYawOutput.u8t[i] = rxdata_servo[65+i];
		   ServoRevTypedef.TurnPitchOutput.u8t[i] = rxdata_servo[69+i];
		   ServoRevTypedef.FSMXOutput.u8t[i] = rxdata_servo[73+i];
		   ServoRevTypedef.FSMYOutput.u8t[i] = rxdata_servo[77+i];
		   #endif
		 }

		 ServoRevTypedef.ServoCrc                     =  rxdata_servo[81];
		 ServoRevTypedef.ServoCheck                   =  rxdata_servo[82];

		//  uart_printf("FSMXPos:%.2f,FSMYPos:%.2f,ServoYawPos:%.2f,ServoPitchPos:%.2f,YawSpeed:%.2f,PitchSpeed:%.2f,FSMXPosZero:%.2f,FSMYPosZero:%.2f,TurnYawOutput:%.2f,TurnPitchOutput:%.2f,FSMXOutput:%.2f,FSMYOutput:%.2f\r\n",ServoRevTypedef.FSMXPos.f,ServoRevTypedef.FSMYPos.f,ServoRevTypedef.ServoYawPos.f,ServoRevTypedef.ServoPitchPos.f,ServoRevTypedef.YawSpeed.f,ServoRevTypedef.PitchSpeed.f,ServoRevTypedef.FSMXPosZero.f,ServoRevTypedef.FSMYPosZero.f,ServoRevTypedef.TurnYawOutput.f,ServoRevTypedef.TurnPitchOutput.f,ServoRevTypedef.FSMXOutput.f,ServoRevTypedef.FSMYOutput.f);
		        // for(int i = 0;i < rxSize;i++)
		        // {
		        //   uart_printf("%02x ",rxdata_servo[i]);
		        // }
//		         打印数据

		//  sprintf(msg,"41:%02x,42:%02x,43:%02x,44:%02x,ServoPitchPos = %.2f, ServoYawPos= %.2f\r\n",rxdata_servo[41],rxdata_servo[42],rxdata_servo[43],rxdata_servo[44],ServoRevTypedef.ServoPitchPos.f, ServoRevTypedef.ServoYawPos.f);
		// 打印错误代码
		// uart_printf()
		// sprintf(msg,"CommunicationFault:%d,EncoderFault:%d,DriverFaultA:%d,DriverFaultE:%d,OverSpeedA:%d,OverSpeedE:%d,ControlOverLimitA:%d,ControlOverLimitE:%d,PositionOverLimitE:%d,PositionUnderLimitE:%d,TrackingFaultCuByte1:%d,TrackingFaultCuByte2:%d,TrackingFaultCuByte3:%d,TrackingFaultCuByte4:%d,yaw:%.2f,pitch:%.2f\r\n",TrackingFaultCodeCu.CommunicationFault,TrackingFaultCodeCu.EncoderFault,TrackingFaultCodeCu.DriverFaultA,TrackingFaultCodeCu.DriverFaultE,TrackingFaultCodeCu.OverSpeedA,TrackingFaultCodeCu.OverSpeedE,TrackingFaultCodeCu.ControlOverLimitA,TrackingFaultCodeCu.ControlOverLimitE,TrackingFaultCodeCu.PositionOverLimitE,TrackingFaultCodeCu.PositionUnderLimitE,TrackingFaultCodeCu.TrackingFaultCuByte1,TrackingFaultCodeCu.TrackingFaultCuByte2,TrackingFaultCodeCu.TrackingFaultCuByte3,TrackingFaultCodeCu.TrackingFaultCuByte4, ServoRevTypedef.ServoYawPos.f,ServoRevTypedef.ServoPitchPos.f);
		//  HAL_UART_Transmit_DMA(&huart5, (uint8_t*)msg, strlen(msg));
		// uart_printf("%s",msg);
//
//		         uint8_t msg1[6] = {0xee,0x16,0x02,0x03,0x01,0x04};
//		         	HAL_UART_Transmit(&huart7, msg1, 6,0xff);
//		         	osDelay(200);
//		         	uint8_t msg3[] = {0xee, 0x16, 0x04, 0x03, 0xa1, 0x0a, 0x00, 0xae};
//		         	HAL_UART_Transmit(&huart7, msg3, 8,0xff);
//		         	osDelay(200);
//		         	uint8_t msg2[6] = {0xee,0x16,0x02,0x03,0x04,0x07};
//		         			         	HAL_UART_Transmit(&huart7, msg2, 6,0xff);
		         //	uint8_t msg[8] = {0xaa, 0x01, 0x08, 0x0f, 0x03, 0x00, 0x64, 0xcb};
//		         uint8_t msg3[7] = {0xaa,0x01,0x07,0x1b,0x03,0x00,0xb4};
//		         HAL_UART_Transmit(&huart6, msg3, 7,0xff);
//		         osDelay(200);
//		         uint8_t msg0[12] = {0xaa, 0x01, 0x0c, 0x01, 0x03, 0x00, 0x44, 0x7a, 0x00, 0x00, 0x00, 0x9b};
//		         		  HAL_GPIO_TogglePin(LED2_GPIO_Port, LED2_Pin);
//		         		  HAL_UART_Transmit_DMA(&huart6, msg0, 12);
//		         		  osDelay(2000);
//		         	uint8_t msg1[12] = {0xaa, 0x01, 0x0c, 0x01, 0x03, 0x00, 0x00, 0x00, 0x00, 0x00, 0x00, 0xa5};
//		         	HAL_UART_Transmit_DMA(&huart6, msg1, 12);
//		         			  osDelay(2000);
//		         			  uint8_t msg2[12] = {0xaa, 0x01, 0x0c, 0x01, 0x03, 0x00, 0xc4, 0x7a, 0x00, 0x00, 0x00, 0x1b};
//		         			  	HAL_UART_Transmit_DMA(&huart6, msg2, 12);
//		         			  			  osDelay(3000);
//		         uint8_t msg4[8] = {0xaa, 0x01, 0x08, 0x0f, 0x03, 0x00, 0x32, 0x9d};
//		         HAL_UART_Transmit(&huart6, msg4, 8,0xff);

		        memset(rxdata_servo,0,sizeof(rxdata_servo));
//		  HAL_UART_Transmit_DMA(&huart5, rxdata_servo, rxSize);
	  }
    osDelay(20);
  }
  /* USER CODE END TurnTask */
}

void ImgCuTask(void const * argument)
{
  /* USER CODE BEGIN ImgCuTask */
  /* Infinite loop */
  for(;;)
  {
	  if(osSemaphoreWait(BinaryCuHandle, 10) == osOK && taskCuBegin == pdTRUE)
	  {
		ImgRecvDataTypedef_CU.code1.SelfCheck     = (rxdata_cu[3] & bit(0)) ? 1 : 0;
		ImgRecvDataTypedef_CU.code1.Standby       = (rxdata_cu[3] & bit(1)) ? 1 : 0;
		ImgRecvDataTypedef_CU.code1.AutoTrack     = (rxdata_cu[3] & bit(2)) ? 1 : 0;
		ImgRecvDataTypedef_CU.code1.ManualTrack   = (rxdata_cu[3] & bit(3)) ? 1 : 0;

		// uart2_printf("selfcheck:%d,standby:%d,autotrack:%d,manualtrack:%d\r\n",ImgRecvDataTypedef_CU.code1.SelfCheck,ImgRecvDataTypedef_CU.code1.Standby,ImgRecvDataTypedef_CU.code1.AutoTrack,ImgRecvDataTypedef_CU.code1.ManualTrack);
		ImgRecvDataTypedef_CU.code2.CheckState    = (rxdata_cu[4] & bit(7)) ? 1 : 0;
		ImgRecvDataTypedef_CU.code2.InitState     = (rxdata_cu[4] & bit(6)) ? 1 : 0;
		ImgRecvDataTypedef_CU.code2.NormalTrack   = (rxdata_cu[4] & bit(5)) ? 1 : 0;
		ImgRecvDataTypedef_CU.code2.RememberTrack = (rxdata_cu[4] & bit(4)) ? 1 : 0;
		ImgRecvDataTypedef_CU.code2.TrackLose     = (rxdata_cu[4] & bit(3)) ? 1 : 0;
		pcSend.cuEnable = ImgRecvDataTypedef_CU.code2.NormalTrack || ImgRecvDataTypedef_CU.code2.RememberTrack;

		// uart2_printf("checkstate:%d,initstate:%d,normaltrack:%d,remembertrack:%d,tracklose:%d\r\n",ImgRecvDataTypedef_CU.code2.CheckState,ImgRecvDataTypedef_CU.code2.InitState,ImgRecvDataTypedef_CU.code2.NormalTrack,ImgRecvDataTypedef_CU.code2.RememberTrack,ImgRecvDataTypedef_CU.code2.TrackLose);

		ImgRecvDataTypedef_CU.WorkState           = rxdata_cu[5];

		ImgRecvDataTypedef_CU.HardVersion         = (uint8_t)(rxdata_cu[8] & 00000111);
		ImgRecvDataTypedef_CU.SoftVersion         = (uint8_t)(rxdata_cu[8] & 01111000);

		ImgRecvDataTypedef_CU.ImgCount            = rxdata_cu[7] << 8 | rxdata_cu[6];
		ImgRecvDataTypedef_CU.DataCount           = rxdata_cu[10] << 8 | rxdata_cu[9];

		int buff[2] = {0,0};
		buff[0]							          = (rxdata_cu[15] << 28 | rxdata_cu[14] << 21 | rxdata_cu[13] << 14 | rxdata_cu[12] << 7 | rxdata_cu[11]);
		buff[1]            						  = (rxdata_cu[20] << 28 | rxdata_cu[19] << 21 | rxdata_cu[18] << 14 | rxdata_cu[17] << 7 | rxdata_cu[16]);
		ImgRecvDataTypedef_CU.Offset_X            = *((float *)&buff[0]);
		ImgRecvDataTypedef_CU.Offset_Y            = *((float *)&buff[1]);
		// uart_printf("11:%02x,12:%02x,13:%02x,14:%02x,15:%02x\r\n",rxdata_cu[11],rxdata_cu[12],rxdata_cu[13],rxdata_cu[14],rxdata_cu[15]);
		// uart_printf("16:%02x,17:%02x,18:%02x,19:%02x,20:%02x\r\n",rxdata_cu[16],rxdata_cu[17],rxdata_cu[18],rxdata_cu[19],rxdata_cu[20]);
		// uart_printf("x:%.2f,y:%.2f\r\n",ImgRecvDataTypedef_CU.Offset_X,ImgRecvDataTypedef_CU.Offset_Y);

		// uart_printf("")

		        // ImgRecvDataTypedef_CU.Offset_X            = (rxdata_cu[15] << 28 | rxdata_cu[14] << 21 | rxdata_cu[13] << 14 | rxdata_cu[12] << 7 | rxdata_cu[11]) / 1.f;
		        // ImgRecvDataTypedef_CU.Offset_Y            = (rxdata_cu[20] << 28 | rxdata_cu[19] << 21 | rxdata_cu[18] << 14 | rxdata_cu[17] << 7 | rxdata_cu[16]) / 1.f;

//		        char msg[128];
		        // sprintf(msg,"x:%.2f,y:%.2f",ImgRecvDataTypedef_CU.Offset_X,ImgRecvDataTypedef_CU.Offset_Y);
		        // HAL_UART_Transmit_DMA(&huart3, (uint8_t *)msg, strlen(msg));
		  memset(rxdata_cu,0,rxSize);
	  }
    osDelay(10);
  }
  /* USER CODE END ImgCuTask */
}

void ImgJingTask(void const * argument)
{
  /* USER CODE BEGIN ImgJingTask */
  /* Infinite loop */
  for(;;)
  {
	  if(osSemaphoreWait(BinaryJingHandle, 10) == osOK && taskJingBegin == pdTRUE)
	  {
		  	ImgRecvDataTypedef_JING.code1.SelfCheck     = (rxdata_jing[3] & bit(0)) ? 1 : 0;
	        ImgRecvDataTypedef_JING.code1.Standby       = (rxdata_jing[3] & bit(1)) ? 1 : 0;
	        ImgRecvDataTypedef_JING.code1.AutoTrack     = (rxdata_jing[3] & bit(2)) ? 1 : 0;
	        ImgRecvDataTypedef_JING.code1.ManualTrack   = (rxdata_jing[3] & bit(3)) ? 1 : 0;

	        ImgRecvDataTypedef_JING.code2.CheckState    = (rxdata_jing[4] & bit(7)) ? 1 : 0;
	        ImgRecvDataTypedef_JING.code2.InitState     = (rxdata_jing[4] & bit(6)) ? 1 : 0;
	        ImgRecvDataTypedef_JING.code2.NormalTrack   = (rxdata_jing[4] & bit(5)) ? 1 : 0;
	        ImgRecvDataTypedef_JING.code2.RememberTrack = (rxdata_jing[4] & bit(4)) ? 1 : 0;
	        ImgRecvDataTypedef_JING.code2.TrackLose     = (rxdata_jing[4] & bit(3)) ? 1 : 0;
			pcSend.jingEnable = ImgRecvDataTypedef_JING.code2.NormalTrack || ImgRecvDataTypedef_JING.code2.RememberTrack;

	        ImgRecvDataTypedef_JING.WorkState           = rxdata_jing[5];

	        ImgRecvDataTypedef_JING.HardVersion         = (uint8_t)(rxdata_jing[8] & 00000111);
	        ImgRecvDataTypedef_JING.SoftVersion         = (uint8_t)(rxdata_jing[8] & 01111000);

	        ImgRecvDataTypedef_JING.ImgCount            = rxdata_jing[7] << 8 | rxdata_jing[6];
	        ImgRecvDataTypedef_JING.DataCount           = rxdata_jing[10] << 8 | rxdata_jing[9];

			int buff[2] = {0,0};
			buff[0]							            = (rxdata_jing[15] << 28 | rxdata_jing[14] << 21 | rxdata_jing[13] << 14 | rxdata_jing[12] << 7 | rxdata_jing[11]);
	        buff[1]            							= (rxdata_jing[20] << 28 | rxdata_jing[19] << 21 | rxdata_jing[18] << 14 | rxdata_jing[17] << 7 | rxdata_jing[16]);
			ImgRecvDataTypedef_JING.Offset_X            = *((float *)&buff[0]);
	        ImgRecvDataTypedef_JING.Offset_Y            = *((float *)&buff[1]);

			// uart_printf("selfcheck:%d,standby:%d,autotrack:%d,manualtrack:%d\r\n",ImgRecvDataTypedef_JING.code1.SelfCheck,ImgRecvDataTypedef_JING.code1.Standby,ImgRecvDataTypedef_JING.code1.AutoTrack,ImgRecvDataTypedef_JING.code1.ManualTrack);
//			uart_printf("checkstate:%d,initstate:%d,normaltrack:%d,remembertrack:%d,tracklose:%d\r\n",ImgRecvDataTypedef_JING.code2.CheckState,ImgRecvDataTypedef_JING.code2.InitState,ImgRecvDataTypedef_JING.code2.NormalTrack,ImgRecvDataTypedef_JING.code2.RememberTrack,ImgRecvDataTypedef_JING.code2.TrackLose);
			// uart_printf("workstate:%d,hardversion:%d,softversion:%d,imgcount:%d,datacount:%d,offsetx:%.2f,offsety:%.2f\r\n",ImgRecvDataTypedef_JING.WorkState,ImgRecvDataTypedef_JING.HardVersion,ImgRecvDataTypedef_JING.SoftVersion,ImgRecvDataTypedef_JING.ImgCount,ImgRecvDataTypedef_JING.DataCount,ImgRecvDataTypedef_JING.Offset_X,ImgRecvDataTypedef_JING.Offset_Y);

//	        char msg[128];
	        // sprintf(msg,"x:%.2f,y:%.2f",ImgRecvDataTypedef_JING.Offset_X,ImgRecvDataTypedef_JING.Offset_Y);
//	         uart_printf("%s",msg);
	        memset(rxdata_cu,0,rxSize);
	  }
    osDelay(10);
  }
  /* USER CODE END ImgJingTask */
}

void FocusTask(void const * argument)
{
  /* USER CODE BEGIN FocusTask */

  /* Infinite loop */
  for(;;)
  {
	  if(osSemaphoreWait(BinaryFocusHandle, 10) == osOK && taskFocusBegin == pdTRUE)
	  {
		  getFocusPos.u8t[3] = rxdata_focus[6];
		  getFocusPos.u8t[2] = rxdata_focus[7];
		  getFocusPos.u8t[1] = rxdata_focus[8];
		  getFocusPos.u8t[0] = rxdata_focus[9];

		        char msg[128];
		        sprintf(msg,"%02x,%02x,%02x,%02x,pos:%f",rxdata_focus[6],rxdata_focus[7],rxdata_focus[8],rxdata_focus[9],getFocusPos.f);
		        // HAL_UART_Transmit(&huart5, (uint8_t *)msg, strlen(msg), 0xff);
				uart_printf("%s",msg);
		        memset(rxdata_focus,0,sizeof(rxdata_focus));
	  }

    osDelay(100);
  }
  /* USER CODE END FocusTask */
}

void RangefinderTask(void const * argument)
{
  /* USER CODE BEGIN RangefinderTask */
	// TODO:掉电�???????要重新设�???????
  /* Infinite loop */
  for(;;)
  {
	  if(osSemaphoreWait(BinaryRangefinderHandle, 10) == osOK && taskRangeBegin == pdTRUE)
	  {
		// 打印数据
		// for(int i = 0;i < rxSize;i++)
	  	// {
		// 	uart_printf("%02x ",rxdata_rangefinder[i]);
		// }

		  switch (rxdata_rangefinder[4])
		        {
		          case DeviceCheck:{
		            RangeFinderRevData.HuiBoValue = rxdata_rangefinder[6];
		            RangeFinderRevData.FPGAState  = rxdata_rangefinder[7] & bit(0) ? 1 : 0;
		            RangeFinderRevData.RayState   = rxdata_rangefinder[7] & bit(1) ? 1 : 0;
		            RangeFinderRevData.ZhuBoState = rxdata_rangefinder[7] & bit(2) ? 1 : 0;
		            RangeFinderRevData.HuiBoState = rxdata_rangefinder[7] & bit(3) ? 1 : 0;
		            RangeFinderRevData.TempState  = rxdata_rangefinder[7] & bit(6) ? 1 : 0;
		            RangeFinderRevData.RayOn      = rxdata_rangefinder[7] & bit(7) ? 1 : 0;
		            RangeFinderRevData.PowerState = rxdata_rangefinder[8] & bit(0) ? 1 : 0;
		          }break;
		          case SingleMeasure:{
		            RangeFinderRevData.Distance   = rxdata_rangefinder[6] * 256 + rxdata_rangefinder[7] + rxdata_rangefinder[8] * 0.1;

		          }break;
		          case MultiMeasure:{
		            RangeFinderRevData.Distance   = rxdata_rangefinder[6] * 256 + rxdata_rangefinder[7] + rxdata_rangefinder[8] * 0.1;
					pcSend.rangefinder.f = RangeFinderRevData.Distance;
				}break;
		          case DeviceError:{
		            RangeFinderRevData.FPGAState  = rxdata_rangefinder[8] & bit(0) ? 1 : 0;
		            RangeFinderRevData.RayState   = rxdata_rangefinder[8] & bit(1) ? 1 : 0;
		            RangeFinderRevData.ZhuBoState = rxdata_rangefinder[8] & bit(2) ? 1 : 0;
		            RangeFinderRevData.HuiBoState = rxdata_rangefinder[8] & bit(3) ? 1 : 0;
		            RangeFinderRevData.TempState  = rxdata_rangefinder[8] & bit(6) ? 1 : 0;
		            RangeFinderRevData.RayOn      = rxdata_rangefinder[8] & bit(7) ? 1 : 0;
		          }break;
		          default:
		            break;
		        }
				// uart_printf("distance:%.2f\r\n",RangeFinderRevData.Distance);
				uart_printf("%x,%x,%x,%.2f\n",rxdata_rangefinder[6],rxdata_rangefinder[7],rxdata_rangefinder[8],RangeFinderRevData.Distance);
		//   char msg[128];
		//         sprintf(msg,"distance = %.2f\r\n",RangeFinderRevData.Distance);
		//         HAL_UART_Transmit_DMA(&huart5, (uint8_t*)msg, strlen(msg));
		        memset(rxdata_rangefinder,0,sizeof(rxdata_rangefinder));
	  }
    osDelay(10);
  }
  /* USER CODE END RangefinderTask */
}

/* USER CODE BEGIN Application */
void HAL_UARTEx_RxEventCallback(UART_HandleTypeDef *huart, uint16_t Size)
{
  /* Prevent unused argument(s) compilation warning */
  UNUSED(huart);
  UNUSED(Size);
  rxSize = Size;
//   static float fPm1, fPm2, fPm3;
// 	static int iPm1, iPm2, iPm3;
  if(huart == &huart5)
  {
	  taskTurnBegin = pdTRUE;
	  if(rxbuff_servo[0] == 0xEB && rxbuff_servo[1] == 0x90 && rxbuff_servo[Size - 1] == 0xFE)
	  {
		  if(osSemaphoreRelease(BinaryServoHandle) == osOK)
		  {
			  memcpy(rxdata_servo,rxbuff_servo,Size);
			  memset(rxbuff_servo,0,Size);
			  HAL_GPIO_TogglePin(LED1_GPIO_Port, LED1_Pin);
		  }
	  }
	  HAL_UARTEx_ReceiveToIdle_DMA(&huart5, rxbuff_servo, 128);
	  __HAL_DMA_DISABLE_IT(&hdma_uart5_rx, DMA_IT_HT);
  }else if(huart == &huart3){
	  taskCuBegin = pdTRUE;
	  if(rxbuff_cu[0] == 0xCC && rxbuff_cu[1] == 0xC0 && rxbuff_cu[Size - 1] == 0xBB)
	  {
		  if(osSemaphoreRelease(BinaryCuHandle) == osOK)
		  {
//			  HAL_UART_Transmit_DMA(&huart3, rxdata_cu, rxSize);
			  memcpy(rxdata_cu,rxbuff_cu,Size);
			  memset(rxbuff_cu,0,Size);
			  HAL_GPIO_TogglePin(LED1_GPIO_Port, LED1_Pin);
		  }
	  }
	  HAL_UARTEx_ReceiveToIdle_DMA(&huart3, rxbuff_cu, 128);
	  __HAL_DMA_DISABLE_IT(&hdma_usart3_rx, DMA_IT_HT);
  }else if(huart == &huart4){
	  taskJingBegin = pdTRUE;
	  if(rxbuff_jing[0] == 0xCC && rxbuff_jing[1] == 0xC0 && rxbuff_jing[Size - 1] == 0xBB)
	  	  {
	  		  if(osSemaphoreRelease(BinaryJingHandle) == osOK)
	  		  {
	  //			  HAL_UART_Transmit_DMA(&huart3, rxdata_cu, rxSize);
	  			  memcpy(rxdata_jing,rxbuff_jing,Size);
	  			  memset(rxbuff_jing,0,Size);
	  			  HAL_GPIO_TogglePin(LED1_GPIO_Port, LED1_Pin);
	  		  }
	  	  }
	  	  HAL_UARTEx_ReceiveToIdle_DMA(&huart4, rxbuff_jing, 128);
	  	  __HAL_DMA_DISABLE_IT(&hdma_uart4_rx, DMA_IT_HT);
  }else if(huart == &huart6){
	  taskFocusBegin = pdTRUE;
	  if(rxbuff_focus[0] == 0xaa && rxbuff_focus[1] == 0x01 && rxbuff_focus[Size - 1] == checkData(rxbuff_focus, Size - 1))
	  {
		uart_printf("enter focus\r\n");
		  if(osSemaphoreRelease(BinaryFocusHandle) == osOK)
		  {
			uart_printf("enter\r\n");
			  memcpy(rxdata_focus,rxbuff_focus,Size);
			  memset(rxbuff_focus,0,Size);
		  HAL_GPIO_TogglePin(LED1_GPIO_Port, LED1_Pin);

		  }
//	  HAL_UART_Transmit_DMA(&huart6,"")
	  }
//		  HAL_UART_Transmit(&huart5, rxbuff_focus, Size, 0xff);
	  HAL_UARTEx_ReceiveToIdle_DMA(&huart6, rxbuff_focus, 11);
	  __HAL_DMA_DISABLE_IT(&hdma_usart6_rx, DMA_IT_HT);

  }else if(huart == &huart7){
	  taskRangeBegin = pdTRUE;
	  if(rxbuff_rangefinder[0] == 0xee && rxbuff_rangefinder[1] == 0x16 && rxbuff_rangefinder[Size - 1] == CheckSumRangefinder(rxbuff_rangefinder + 3, rxbuff_rangefinder[2]))
	  {
		  if(osSemaphoreRelease(BinaryRangefinderHandle) == osOK)
		  {
			  memcpy(rxdata_rangefinder,rxbuff_rangefinder,Size);
			  memset(rxbuff_rangefinder,0,Size);
			  HAL_GPIO_TogglePin(LED1_GPIO_Port, LED1_Pin);
		  }
	  }

	  HAL_UARTEx_ReceiveToIdle_DMA(&huart7, rxbuff_rangefinder, 128);
	  __HAL_DMA_DISABLE_IT(&hdma_uart7_rx, DMA_IT_HT);
  }
  else if(huart == &huart2)
  {
	static float fPm1, fPm2, fPm3;
	static int iPm1, iPm2, iPm3;

	switch(chcmd[0])
	{
		case 'M':{
			sscanf(chcmd + 1,"%x", &iPm1);
			ServoDataSendTypedef.TurnMode = iPm1;
			ServoDataSend(&ServoSendTypedef,&ServoDataSendTypedef);

		}break;
		case 'P':{
			sscanf(chcmd + 1,"%f,%f", &fPm1, &fPm2, &fPm3);
			CommandTypedef.turnYaw.f = fPm1;
			CommandTypedef.turnPitch.f = fPm2;
		}break;
		case 'S':{
			sscanf(chcmd + 1,"%d", &iPm1);
			switch(iPm1)
			{
				case 0:{
					CommandTypedef.go2Zero = 0x01;
					CommandTypedef.standbyEnable = 0x00;
					CommandTypedef.standbyDisable = 0x00;
					CommandTypedef.guideEnable = 0x00;
					CommandTypedef.scanEnable = 0x00;
				}break;
				case 1:{
					CommandTypedef.go2Zero = 0x00;
					CommandTypedef.standbyEnable = 0x01;
					CommandTypedef.standbyDisable = 0x00;
					CommandTypedef.guideEnable = 0x00;
					CommandTypedef.scanEnable = 0x00;
				}break;
				case 2:{
					CommandTypedef.go2Zero = 0x00;
					CommandTypedef.standbyEnable = 0x00;
					CommandTypedef.standbyDisable = 0x01;
					CommandTypedef.guideEnable = 0x00;
					CommandTypedef.scanEnable = 0x00;
				}break;
				case 3:{
					CommandTypedef.go2Zero = 0x00;
					CommandTypedef.standbyEnable = 0x00;
					CommandTypedef.standbyDisable = 0x00;
					CommandTypedef.guideEnable = 0x01;
					CommandTypedef.scanEnable = 0x00;
				}break;
				case 4:{
					CommandTypedef.go2Zero = 0x00;
					CommandTypedef.standbyEnable = 0x00;
					CommandTypedef.standbyDisable = 0x00;
					CommandTypedef.guideEnable = 0x00;
					CommandTypedef.scanEnable = 0x01;
				}break;
				default:
					break;
			}

		}break;
		case 'V':{
			sscanf(chcmd + 1,"%d,%d", &iPm1, &iPm2);
			CommandTypedef.turnYawSpeed = iPm1 * 100;
			CommandTypedef.turnPitchSpeed = iPm2 * 100;
			// ServoDataSendTypedef.Turntable_Yaw = fPm1;
			// ServoDataSendTypedef.Turntable_Pitch = fPm2;
		}break;
		case 'C':{
			ServoDataSendTypedef.TrackingFaultCleanCu = 0x66;
			ServoDataSendTypedef.TrackingFaultCleanJing = 0x33;
		}break;
		case 'F':{
			sscanf(chcmd + 1,"%f,%f", &fPm1, &fPm2);
			CommandTypedef.FSM_Yaw.f = fPm1;
			CommandTypedef.FSM_Pitch.f = fPm2;
		}break;
		default:
		break;
	}

	HAL_UART_Transmit(&huart2, chcmd, Size, 0xff);
	HAL_UARTEx_ReceiveToIdle_DMA(&huart2, (uint8_t *)chcmd, 64);
	__HAL_DMA_DISABLE_IT(&hdma_usart2_rx, DMA_IT_HT);
  }
//  else if(huart == &huart2)
//  {
// 	HAL_GPIO_TogglePin(LED1_GPIO_Port, LED1_Pin);
// 	switch(uartbuff[0])
// 	{
// 		case 'E':{
// 			sscanf(uartbuff + 1,"%ld,%ld,%ld,%ld",&pcRecv.exposurecu,&pcRecv.exposurejing,&pcRecv.focusAdjust_cu, &pcRecv.zoomAdjust_cu);

// 		}break;
// 		case 'M':{
// 			sscanf(uartbuff + 1,"%d",&state);
// 			switch(state)
// 			{
// 				case 1:{
// 					CommandTypedef.go2Zero = 0x01;
// 					CommandTypedef.standbyEnable = 0x00;
// 					CommandTypedef.standbyDisable = 0x00;
// 					CommandTypedef.guideEnable = 0x00;
// 					CommandTypedef.scanEnable = 0x00;
// 				}break;
// 				case 2:{
// 					CommandTypedef.go2Zero = 0x00;
// 					CommandTypedef.standbyEnable = 0x01;
// 					CommandTypedef.standbyDisable = 0x00;
// 					CommandTypedef.guideEnable = 0x00;
// 					CommandTypedef.scanEnable = 0x00;
// 				}break;
// 				case 3:{
// 					CommandTypedef.go2Zero = 0x00;
// 					CommandTypedef.standbyEnable = 0x00;
// 					CommandTypedef.standbyDisable = 0x01;
// 					CommandTypedef.guideEnable = 0x00;
// 					CommandTypedef.scanEnable = 0x00;
// 				}break;
// 				case 4:{
// 					CommandTypedef.go2Zero = 0x00;
// 					CommandTypedef.standbyEnable = 0x00;
// 					CommandTypedef.standbyDisable = 0x00;
// 					CommandTypedef.guideEnable = 0x01;
// 					CommandTypedef.scanEnable = 0x00;
// 				}break;
// 				case 5:{
// 					CommandTypedef.go2Zero = 0x00;
// 					CommandTypedef.standbyEnable = 0x00;
// 					CommandTypedef.standbyDisable = 0x00;
// 					CommandTypedef.guideEnable = 0x00;
// 					CommandTypedef.scanEnable = 0x01;
// 				}break;
// 			}
// 		}break;

// 	}
// 	// uart_printf("%d\r\n",state);
// 	// uart_printf("exposurecu:%ld,exposurejing:%ld,focusAdjust_cu:%ld,zoomAdjust_cu:%ld\r\n",pcRecv.exposurecu,pcRecv.exposurejing,pcRecv.focusAdjust_cu,pcRecv.zoomAdjust_cu);
// 	HAL_UARTEx_ReceiveToIdle_IT(&huart2, uartbuff, 16);
// 	__HAL_DMA_DISABLE_IT(&hdma_usart2_rx, DMA_IT_HT);
//  }
  /* NOTE : This function should not be modified, when the callback is needed,
            the HAL_UARTEx_RxEventCallback can be implemented in the user file.
   */
}
// uint8_t cmd_i = 0;
// void HAL_UART_RxCpltCallback(UART_HandleTypeDef *huart)
// {
//   /* Prevent unused argument(s) compilation warning */
//   UNUSED(huart);
// 	if(huart == &huart2)
// 	{

// 	if(chcmd[cmd_i] == '\n')
// 	{
// 		chcmd[cmd_i + 1] = '\0';
// 		switch(chcmd[cmd_start])
// 		{
// 			case 'E':{
// 				// uart_printf("%s",chcmd + cmd_start + 1);
// 				uart2_printf("%s",chcmd + cmd_start + 1);
// 				// HAL_UART_Transmit(&huart2, chcmd + cmd_start + 1, cmd_i - cmd_start, 0xff);
// 				// sscanf(chcmd + cmd_start + 1,"%ld,%ld,%ld,%ld",&pcRecv.exposurecu,&pcRecv.exposurejing,&pcRecv.focusAdjust_cu, &pcRecv.zoomAdjust_cu);
// 			}break;
// 			case 'M':{
// 				sscanf(chcmd + cmd_start + 1,"%d",&state);
// 				switch(state)
// 				{
// 					case 1:{
// 						CommandTypedef.go2Zero = 0x01;
// 						CommandTypedef.standbyEnable = 0x00;
// 						CommandTypedef.standbyDisable = 0x00;
// 						CommandTypedef.guideEnable = 0x00;
// 						CommandTypedef.scanEnable = 0x00;
// 					}break;
// 					case 2:{
// 						CommandTypedef.go2Zero = 0x00;
// 						CommandTypedef.standbyEnable = 0x01;
// 						CommandTypedef.standbyDisable = 0x00;
// 						CommandTypedef.guideEnable = 0x00;
// 						CommandTypedef.scanEnable = 0x00;
// 					}break;
// 					case 3:{
// 						CommandTypedef.go2Zero = 0x00;
// 						CommandTypedef.standbyEnable = 0x00;
// 						CommandTypedef.standbyDisable = 0x01;
// 						CommandTypedef.guideEnable = 0x00;
// 						CommandTypedef.scanEnable = 0x00;
// 					}break;
// 					case 4:{
// 						CommandTypedef.go2Zero = 0x00;
// 						CommandTypedef.standbyEnable = 0x00;
// 						CommandTypedef.standbyDisable = 0x00;
// 						CommandTypedef.guideEnable = 0x01;
// 						CommandTypedef.scanEnable = 0x00;
// 					}break;
// 					case 5:{
// 						CommandTypedef.go2Zero = 0x00;
// 						CommandTypedef.standbyEnable = 0x00;
// 						CommandTypedef.standbyDisable = 0x00;
// 						CommandTypedef.guideEnable = 0x00;
// 						CommandTypedef.scanEnable = 0x01;
// 					}break;
// 				}
// 			}break;
// 			default:
// 				break;
// 		}
// 		cmd_i = 0;
// 	}
// 	else
// 	{
// 		cmd_i++;
// 	}
// 	// uart_printf("%s",chcmd);
// 	HAL_GPIO_WritePin(LED2_GPIO_Port,LED2_Pin,GPIO_PIN_RESET);
// 	HAL_UART_Receive_IT(&huart2, (uint8_t*)&chcmd[cmd_i], 1);

// 	}
//   /* NOTE : This function should not be modified, when the callback is needed,
//             the HAL_UART_RxCpltCallback can be implemented in the user file.
//    */
// }

void HAL_UART_ErrorCallback(UART_HandleTypeDef *huart)
{
  /* Prevent unused argument(s) compilation warning */
  UNUSED(huart);
  if(huart == &huart5)
  {
	  HAL_UARTEx_ReceiveToIdle_DMA(&huart5, rxbuff_servo, 128);
	   __HAL_DMA_DISABLE_IT(&hdma_uart5_rx, DMA_IT_HT);

  }else if(huart == &huart3)
  {
	  HAL_UARTEx_ReceiveToIdle_DMA(&huart3, rxbuff_cu, 128);
	  __HAL_DMA_DISABLE_IT(&hdma_usart3_rx, DMA_IT_HT);
  }else if(huart == &huart4)
  {
	  HAL_UARTEx_ReceiveToIdle_DMA(&huart4, rxbuff_jing, 128);
	  	  	  __HAL_DMA_DISABLE_IT(&hdma_uart4_rx, DMA_IT_HT);
  }else if(huart == &huart6)
  {

	  HAL_UARTEx_ReceiveToIdle_IT(&huart6, rxbuff_focus, 11);
	  __HAL_DMA_DISABLE_IT(&hdma_usart6_rx, DMA_IT_HT);
  }else if(huart == &huart7)
  {
	  HAL_UARTEx_ReceiveToIdle_DMA(&huart7, rxbuff_rangefinder, 128);
	  __HAL_DMA_DISABLE_IT(&hdma_uart7_rx, DMA_IT_HT);
  }
	else if(huart == &huart2)
	{
		// HAL_GPIO_TogglePin(LED2_GPIO_Port,LED2_Pin);
		// uart_printf("error");
		HAL_UARTEx_ReceiveToIdle_DMA(&huart2, (uint8_t *)chcmd, 16);
		__HAL_DMA_DISABLE_IT(&hdma_usart2_rx, DMA_IT_HT);
	}
  /* NOTE : This function should not be modified, when the callback is needed,
            the HAL_UART_ErrorCallback can be implemented in the user file.
   */
}

void mytask(void const * argument)
{
	static switchFlag = 0;
	osDelay(5000);

  /* USER CODE BEGIN mytask */
  /* Infinite loop */
  for(;;)
  {
	// if(switchFlag == 0)
	// {
	// 	CommandTypedef.laserAdjust += 50;
	// 	if(CommandTypedef.laserAdjust == 6500)
	// 	{
	// 		switchFlag = 1;
	// 	}

	// }
	// else if(switchFlag == 1)
	// {
	// 	CommandTypedef.laserAdjust -= 50;
	// 	if(CommandTypedef.laserAdjust == 50)
	// 	{
	// 		switchFlag = 0;
	// 	}
	// }
	// setFocusPos.f = (float)CommandTypedef.laserAdjust;
	// SendFocusFrame.func = SetPos;
	// SendFocusData(&SendFocusFrame);
	// uart_printf("laserAdjust:%f\r\n",setFocusPos.f);
	// osDelay(100);

	Send2ImgModule(&ImgSendTypedef_JING,&ImgSendDataTypedef_JING);
	osDelay(500);
  }
  /* USER CODE END mytask */
}

/* USER CODE END Application */
